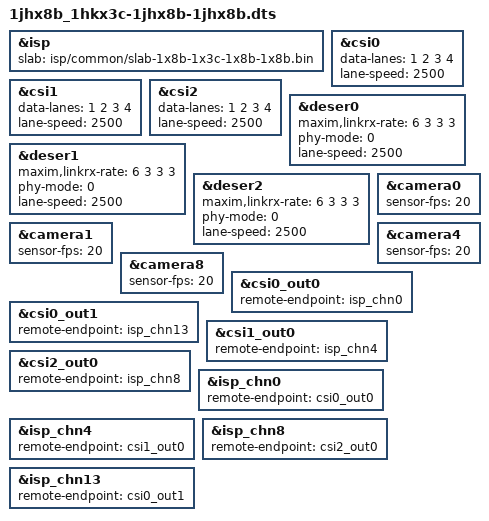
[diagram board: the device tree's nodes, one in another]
/dts-v1/;
/plugin/;

#include "base-isp-msgbox.dtsi"
#include "base-csi-deser-camera.dtsi"
#include "base-desers-3max96724.dtsi"

&isp {
	slab = "isp/common/slab-1x8b-1x3c-1x8b-1x8b.bin";
};
&csi0 {
	status = "okay";
	data-lanes = <1 2 3 4>;
	lane-speed = <2500>;
};
&csi1 {
	status = "okay";
	data-lanes = <1 2 3 4>;
	lane-speed = <2500>;
};
&csi2 {
	status = "okay";
	data-lanes = <1 2 3 4>;
	lane-speed = <2500>;
};
&deser0 {
	maxim,linkrx-rate = <6 3 3 3>;
	phy-mode = <0>;
	lane-speed = <2500>;
};
&deser1 {
	maxim,linkrx-rate = <6 3 3 3>;
	phy-mode = <0>;
	lane-speed = <2500>;
};
&deser2 {
	maxim,linkrx-rate = <6 3 3 3>;
	phy-mode = <0>;
	lane-speed = <2500>;
};
&camera0 {
	#include "../cameras/ox08b_raw14_jh_1920x1080.dtsi"
	sensor-fps = <20>;
	status = "okay";
};
&camera1 {
	#include "../cameras/ox3c_raw14_hk_1920x1080.dtsi"
	sensor-fps = <20>;
	status = "okay";
};
&camera4 {
	#include "../cameras/ox08b_raw14_jh_1920x1080.dtsi"
	sensor-fps = <20>;
	status = "okay";
};
&camera8 {
	#include "../cameras/ox08b_raw14_jh_1920x1080.dtsi"
	sensor-fps = <20>;
	status = "okay";
};
&csi0_out0 {
	remote-endpoint = <&isp_chn0>;
};
&csi0_out1 {
	remote-endpoint = <&isp_chn13>;
};
&csi1_out0 {
	remote-endpoint = <&isp_chn4>;
};
&csi2_out0 {
	remote-endpoint = <&isp_chn8>;
};

&isp_chn0 {
	remote-endpoint = <&csi0_out0>;
};
&isp_chn4 {
	remote-endpoint = <&csi1_out0>;
};
&isp_chn8 {
	remote-endpoint = <&csi2_out0>;
};
&isp_chn13 {
	remote-endpoint = <&csi0_out1>;
};
